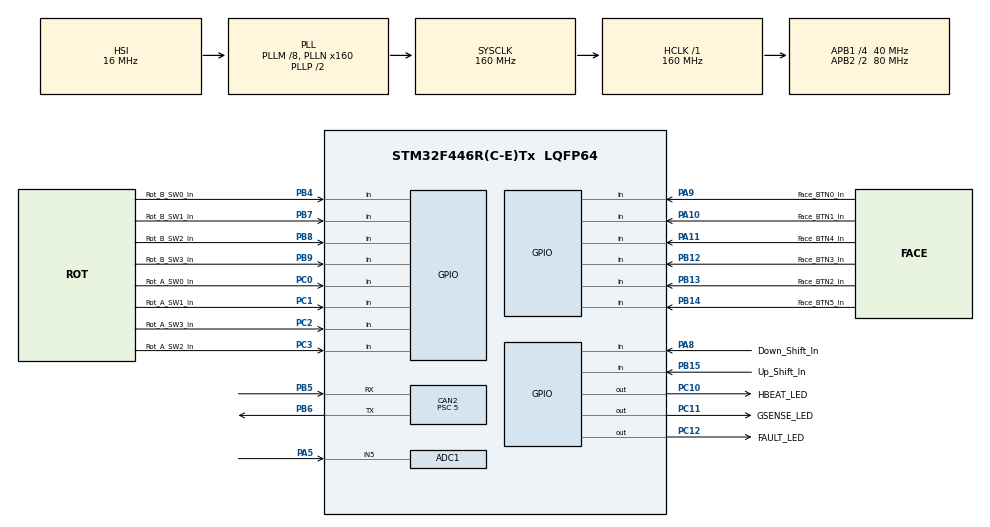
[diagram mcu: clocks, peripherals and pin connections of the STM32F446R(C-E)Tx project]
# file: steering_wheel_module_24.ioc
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ADC1.Channel-0\#ChannelRegularConversion=ADC_CHANNEL_5
ADC1.NbrOfConversionFlag=1
ADC1.Rank-0\#ChannelRegularConversion=1
ADC1.SamplingTime-0\#ChannelRegularConversion=ADC_SAMPLETIME_3CYCLES
ADC1.master=1
CAN2.ABOM=ENABLE
CAN2.AWUM=ENABLE
CAN2.BS1=CAN_BS1_6TQ
CAN2.BS2=CAN_BS2_1TQ
CAN2.CalculateBaudRate=1000000
CAN2.CalculateTimeBit=1000
CAN2.CalculateTimeQuantum=125.0
CAN2.Prescaler=5
FREERTOS.MEMORY_ALLOCATION=2
FREERTOS.Tasks01=main_task,0,1024,task_MainTask,Default,NULL,Static,main_taskBuffer,main_taskControlBlock;buffer_handling,1,1024,task_BufferHandling,Default,NULL,Static,buffer_handlingBuffer,buffer_handlingControlBlock
FREERTOS.configENABLE_FPU=1
FREERTOS.configMINIMAL_STACK_SIZE=512
Mcu.Family=STM32F4
Mcu.Name=STM32F446R(C-E)Tx
Mcu.Package=LQFP64
NVIC.CAN2_RX0_IRQn=true\:5\:0\:false\:false\:true\:true\:true\:true\:true
NVIC.CAN2_RX1_IRQn=true\:5\:0\:false\:false\:true\:true\:true\:true\:true
NVIC.CAN2_TX_IRQn=true\:5\:0\:false\:false\:true\:true\:true\:true\:true
NVIC.PriorityGroup=NVIC_PRIORITYGROUP_4
NVIC.TIM6_DAC_IRQn=true\:15\:0\:false\:false\:true\:false\:false\:true\:true
NVIC.TimeBase=TIM6_DAC_IRQn
NVIC.TimeBaseIP=TIM6
PA10.GPIO_Label=Face_BTN1_In
PA10.Signal=GPIO_Input
PA11.GPIO_Label=Face_BTN4_In
PA11.Signal=GPIO_Input
PA13.Signal=SYS_JTMS-SWDIO
PA14.Signal=SYS_JTCK-SWCLK
PA2.Signal=USART2_TX
PA3.Signal=USART2_RX
PA5.Signal=ADCx_IN5
PA8.GPIO_Label=Down_Shift_In
PA8.Signal=GPIO_Input
PA9.GPIO_Label=Face_BTN0_In
PA9.Signal=GPIO_Input
PB12.GPIO_Label=Face_BTN3_In
PB12.Signal=GPIO_Input
PB13.GPIO_Label=Face_BTN2_In
PB13.Signal=GPIO_Input
PB14.GPIO_Label=Face_BTN5_In
PB14.Signal=GPIO_Input
PB15.GPIO_Label=Up_Shift_In
PB15.Signal=GPIO_Input
PB3.Signal=SYS_JTDO-SWO
PB4.GPIO_Label=Rot_B_SW0_In
PB4.Signal=GPIO_Input
PB5.Mode=CAN_Activate
PB5.Signal=CAN2_RX
PB6.Mode=CAN_Activate
PB6.Signal=CAN2_TX
PB7.GPIO_Label=Rot_B_SW1_In
PB7.Signal=GPIO_Input
PB8.GPIO_Label=Rot_B_SW2_In
PB8.Signal=GPIO_Input
PB9.GPIO_Label=Rot_B_SW3_In
PB9.Signal=GPIO_Input
PC0.GPIO_Label=Rot_A_SW0_In
PC0.Signal=GPIO_Input
PC1.GPIO_Label=Rot_A_SW1_In
PC1.Signal=GPIO_Input
PC10.GPIO_Label=HBEAT_LED
PC10.Signal=GPIO_Output
PC11.GPIO_Label=GSENSE_LED
PC11.Signal=GPIO_Output
PC12.GPIO_Label=FAULT_LED
PC12.Signal=GPIO_Output
PC2.GPIO_Label=Rot_A_SW3_In
PC2.Signal=GPIO_Input
PC3.GPIO_Label=Rot_A_SW2_In
PC3.Signal=GPIO_Input
PH0-OSC_IN.Mode=HSE-External-Clock-Source
PH0-OSC_IN.Signal=RCC_OSC_IN
PH1-OSC_OUT.Mode=HSE-External-Clock-Source
PH1-OSC_OUT.Signal=RCC_OSC_OUT
ProjectManager.HeapSize=0x200
ProjectManager.StackSize=0x400
ProjectManager.TargetToolchain=STM32CubeIDE
RCC.AHBFreq_Value=160000000
RCC.APB1CLKDivider=RCC_HCLK_DIV4
RCC.APB1Freq_Value=40000000
RCC.APB1TimFreq_Value=80000000
RCC.APB2CLKDivider=RCC_HCLK_DIV2
RCC.APB2Freq_Value=80000000
RCC.APB2TimFreq_Value=160000000
RCC.CortexFreq_Value=160000000
RCC.HCLKFreq_Value=160000000
RCC.HSE_VALUE=24000000
RCC.PLLM=8
RCC.PLLN=160
RCC.SYSCLKFreq_VALUE=160000000
RCC.SYSCLKSource=RCC_SYSCLKSOURCE_PLLCLK
RCC.USBFreq_Value=160000000
RCC.VCOOutputFreq_Value=320000000
SH.ADCx_IN5.0=ADC1_IN5,IN5
VP_FREERTOS_VS_CMSIS_V1.Mode=CMSIS_V1
VP_SYS_VS_tim6.Mode=TIM6
VP_TIM10_VS_ClockSourceINT.Mode=Enable_Timer
board=custom

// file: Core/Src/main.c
/* USER CODE BEGIN Header */
/**
  ******************************************************************************
  * @file           : main.c
  * @brief          : Main program body
  ******************************************************************************
  * @attention
  *
  * Copyright (c) 2022 STMicroelectronics.
  * All rights reserved.
  *
  * This software is licensed under terms that can be found in the LICENSE file
  * in the root directory of this software component.
  * If no LICENSE file comes with this software, it is provided AS-IS.
  *
  ******************************************************************************
  */
/* USER CODE END Header */
#include "main.h"
#include "cmsis_os.h"

/* USER CODE BEGIN Includes */
#include "gopher_sense.h"
#include "steering_wheel.h"
/* USER CODE END Includes */

ADC_HandleTypeDef hadc1;

CAN_HandleTypeDef hcan2;

TIM_HandleTypeDef htim10;

osThreadId main_taskHandle;
uint32_t main_taskBuffer[ 1024 ];
osStaticThreadDef_t main_taskControlBlock;
osThreadId buffer_handlingHandle;
uint32_t buffer_handlingBuffer[ 1024 ];
osStaticThreadDef_t buffer_handlingControlBlock;

void SystemClock_Config(void);
static void MX_GPIO_Init(void);
static void MX_CAN2_Init(void);
static void MX_TIM10_Init(void);
static void MX_ADC1_Init(void);
void task_MainTask(void const * argument);
void task_BufferHandling(void const * argument);

int main(void)
{

  /* MCU Configuration--------------------------------------------------------*/

  /* Reset of all peripherals, Initializes the Flash interface and the Systick. */
  HAL_Init();

  /* Configure the system clock */
  SystemClock_Config();

  /* Initialize all configured peripherals */
  MX_GPIO_Init();
  MX_CAN2_Init();
  MX_TIM10_Init();
  MX_ADC1_Init();
  /* USER CODE BEGIN 2 */

  init(&hcan2);
  gsense_init(&hcan2, GSENSE_LED_GPIO_Port, GSENSE_LED_Pin);
  /* USER CODE END 2 */

  /* Create the thread(s) */
  /* definition and creation of main_task */
  osThreadStaticDef(main_task, task_MainTask, osPriorityNormal, 0, 1024, main_taskBuffer, &main_taskControlBlock);
  main_taskHandle = osThreadCreate(osThread(main_task), NULL);

  /* definition and creation of buffer_handling */
  osThreadStaticDef(buffer_handling, task_BufferHandling, osPriorityAboveNormal, 0, 1024, buffer_handlingBuffer, &buffer_handlingControlBlock);
  buffer_handlingHandle = osThreadCreate(osThread(buffer_handling), NULL);

  /* Start scheduler */
  osKernelStart();

  /* We should never get here as control is now taken by the scheduler */
  /* Infinite loop */
  while (1)
  {

  }
}

void SystemClock_Config(void)
{
  RCC_OscInitTypeDef RCC_OscInitStruct = {0};
  RCC_ClkInitTypeDef RCC_ClkInitStruct = {0};

  /** Configure the main internal regulator output voltage
  */
  __HAL_RCC_PWR_CLK_ENABLE();
  __HAL_PWR_VOLTAGESCALING_CONFIG(PWR_REGULATOR_VOLTAGE_SCALE1);

  /** Initializes the RCC Oscillators according to the specified parameters
  * in the RCC_OscInitTypeDef structure.
  */
  RCC_OscInitStruct.OscillatorType = RCC_OSCILLATORTYPE_HSI;
  RCC_OscInitStruct.HSIState = RCC_HSI_ON;
  RCC_OscInitStruct.HSICalibrationValue = RCC_HSICALIBRATION_DEFAULT;
  RCC_OscInitStruct.PLL.PLLState = RCC_PLL_ON;
  RCC_OscInitStruct.PLL.PLLSource = RCC_PLLSOURCE_HSI;
  RCC_OscInitStruct.PLL.PLLM = 8;
  RCC_OscInitStruct.PLL.PLLN = 160;
  RCC_OscInitStruct.PLL.PLLP = RCC_PLLP_DIV2;
  RCC_OscInitStruct.PLL.PLLQ = 2;
  RCC_OscInitStruct.PLL.PLLR = 2;
  if (HAL_RCC_OscConfig(&RCC_OscInitStruct) != HAL_OK)
  {
    Error_Handler();
  }

  /** Initializes the CPU, AHB and APB buses clocks
  */
  RCC_ClkInitStruct.ClockType = RCC_CLOCKTYPE_HCLK|RCC_CLOCKTYPE_SYSCLK
                              |RCC_CLOCKTYPE_PCLK1|RCC_CLOCKTYPE_PCLK2;
  RCC_ClkInitStruct.SYSCLKSource = RCC_SYSCLKSOURCE_PLLCLK;
  RCC_ClkInitStruct.AHBCLKDivider = RCC_SYSCLK_DIV1;
  RCC_ClkInitStruct.APB1CLKDivider = RCC_HCLK_DIV4;
  RCC_ClkInitStruct.APB2CLKDivider = RCC_HCLK_DIV2;

  if (HAL_RCC_ClockConfig(&RCC_ClkInitStruct, FLASH_LATENCY_5) != HAL_OK)
  {
    Error_Handler();
  }
}

static void MX_ADC1_Init(void)
{

  ADC_ChannelConfTypeDef sConfig = {0};

  /** Configure the global features of the ADC (Clock, Resolution, Data Alignment and number of conversion)
  */
  hadc1.Instance = ADC1;
  hadc1.Init.ClockPrescaler = ADC_CLOCK_SYNC_PCLK_DIV4;
  hadc1.Init.Resolution = ADC_RESOLUTION_12B;
  hadc1.Init.ScanConvMode = DISABLE;
  hadc1.Init.ContinuousConvMode = DISABLE;
  hadc1.Init.DiscontinuousConvMode = DISABLE;
  hadc1.Init.ExternalTrigConvEdge = ADC_EXTERNALTRIGCONVEDGE_NONE;
  hadc1.Init.ExternalTrigConv = ADC_SOFTWARE_START;
  hadc1.Init.DataAlign = ADC_DATAALIGN_RIGHT;
  hadc1.Init.NbrOfConversion = 1;
  hadc1.Init.DMAContinuousRequests = DISABLE;
  hadc1.Init.EOCSelection = ADC_EOC_SINGLE_CONV;
  if (HAL_ADC_Init(&hadc1) != HAL_OK)
  {
    Error_Handler();
  }

  /** Configure for the selected ADC regular channel its corresponding rank in the sequencer and its sample time.
  */
  sConfig.Channel = ADC_CHANNEL_5;
  sConfig.Rank = 1;
  sConfig.SamplingTime = ADC_SAMPLETIME_3CYCLES;
  if (HAL_ADC_ConfigChannel(&hadc1, &sConfig) != HAL_OK)
  {
    Error_Handler();
  }

}

static void MX_CAN2_Init(void)
{

  hcan2.Instance = CAN2;
  hcan2.Init.Prescaler = 5;
  hcan2.Init.Mode = CAN_MODE_NORMAL;
  hcan2.Init.SyncJumpWidth = CAN_SJW_1TQ;
  hcan2.Init.TimeSeg1 = CAN_BS1_6TQ;
  hcan2.Init.TimeSeg2 = CAN_BS2_1TQ;
  hcan2.Init.TimeTriggeredMode = DISABLE;
  hcan2.Init.AutoBusOff = ENABLE;
  hcan2.Init.AutoWakeUp = ENABLE;
  hcan2.Init.AutoRetransmission = DISABLE;
  hcan2.Init.ReceiveFifoLocked = DISABLE;
  hcan2.Init.TransmitFifoPriority = DISABLE;
  if (HAL_CAN_Init(&hcan2) != HAL_OK)
  {
    Error_Handler();
  }

}

static void MX_TIM10_Init(void)
{

  htim10.Instance = TIM10;
  htim10.Init.Prescaler = 0;
  htim10.Init.CounterMode = TIM_COUNTERMODE_UP;
  htim10.Init.Period = 65535;
  htim10.Init.ClockDivision = TIM_CLOCKDIVISION_DIV1;
  htim10.Init.AutoReloadPreload = TIM_AUTORELOAD_PRELOAD_DISABLE;
  if (HAL_TIM_Base_Init(&htim10) != HAL_OK)
  {
    Error_Handler();
  }

}

static void MX_GPIO_Init(void)
{
  GPIO_InitTypeDef GPIO_InitStruct = {0};

  /* GPIO Ports Clock Enable */
  __HAL_RCC_GPIOH_CLK_ENABLE();
  __HAL_RCC_GPIOC_CLK_ENABLE();
  __HAL_RCC_GPIOA_CLK_ENABLE();
  __HAL_RCC_GPIOB_CLK_ENABLE();

  /*Configure GPIO pin Output Level */
  HAL_GPIO_WritePin(GPIOC, HBEAT_LED_Pin|GSENSE_LED_Pin|FAULT_LED_Pin, GPIO_PIN_RESET);

  /*Configure GPIO pins : Rot_A_SW0_In_Pin Rot_A_SW1_In_Pin Rot_A_SW3_In_Pin Rot_A_SW2_In_Pin */
  GPIO_InitStruct.Pin = Rot_A_SW0_In_Pin|Rot_A_SW1_In_Pin|Rot_A_SW3_In_Pin|Rot_A_SW2_In_Pin;
  GPIO_InitStruct.Mode = GPIO_MODE_INPUT;
  GPIO_InitStruct.Pull = GPIO_NOPULL;
  HAL_GPIO_Init(GPIOC, &GPIO_InitStruct);

  /*Configure GPIO pins : PA2 PA3 */
  GPIO_InitStruct.Pin = GPIO_PIN_2|GPIO_PIN_3;
  GPIO_InitStruct.Mode = GPIO_MODE_AF_PP;
  GPIO_InitStruct.Pull = GPIO_NOPULL;
  GPIO_InitStruct.Speed = GPIO_SPEED_FREQ_VERY_HIGH;
  GPIO_InitStruct.Alternate = GPIO_AF7_USART2;
  HAL_GPIO_Init(GPIOA, &GPIO_InitStruct);

  /*Configure GPIO pins : Face_BTN3_In_Pin Face_BTN2_In_Pin Face_BTN5_In_Pin Up_Shift_In_Pin
                           Rot_B_SW0_In_Pin Rot_B_SW1_In_Pin Rot_B_SW2_In_Pin Rot_B_SW3_In_Pin */
  GPIO_InitStruct.Pin = Face_BTN3_In_Pin|Face_BTN2_In_Pin|Face_BTN5_In_Pin|Up_Shift_In_Pin
                          |Rot_B_SW0_In_Pin|Rot_B_SW1_In_Pin|Rot_B_SW2_In_Pin|Rot_B_SW3_In_Pin;
  GPIO_InitStruct.Mode = GPIO_MODE_INPUT;
  GPIO_InitStruct.Pull = GPIO_NOPULL;
  HAL_GPIO_Init(GPIOB, &GPIO_InitStruct);

  /*Configure GPIO pins : Down_Shift_In_Pin Face_BTN0_In_Pin Face_BTN1_In_Pin Face_BTN4_In_Pin */
  GPIO_InitStruct.Pin = Down_Shift_In_Pin|Face_BTN0_In_Pin|Face_BTN1_In_Pin|Face_BTN4_In_Pin;
  GPIO_InitStruct.Mode = GPIO_MODE_INPUT;
  GPIO_InitStruct.Pull = GPIO_NOPULL;
  HAL_GPIO_Init(GPIOA, &GPIO_InitStruct);

  /*Configure GPIO pins : HBEAT_LED_Pin GSENSE_LED_Pin FAULT_LED_Pin */
  GPIO_InitStruct.Pin = HBEAT_LED_Pin|GSENSE_LED_Pin|FAULT_LED_Pin;
  GPIO_InitStruct.Mode = GPIO_MODE_OUTPUT_PP;
  GPIO_InitStruct.Pull = GPIO_NOPULL;
  GPIO_InitStruct.Speed = GPIO_SPEED_FREQ_LOW;
  HAL_GPIO_Init(GPIOC, &GPIO_InitStruct);

}

void task_MainTask(void const * argument)
{
  /* USER CODE BEGIN 5 */
  /* Infinite loop */
  for(;;)
  {
	  main_loop();
	  osDelay(10);
  }
  /* USER CODE END 5 */
}

void task_BufferHandling(void const * argument)
{
  /* USER CODE BEGIN task_BufferHandling */
  /* Infinite loop */
  for(;;)
  {
	  can_buffer_handling_loop();
    osDelay(1);
  }
  /* USER CODE END task_BufferHandling */
}

void HAL_TIM_PeriodElapsedCallback(TIM_HandleTypeDef *htim)
{
  if (htim->Instance == TIM6) {
    HAL_IncTick();
  }
  /* USER CODE BEGIN Callback 1 */
  else{
	  //DAQ_TimerCallback(htim);
  }
  /* USER CODE END Callback 1 */
}

void Error_Handler(void)
{
  __disable_irq();
  while (1)
  {
  }
}
